# PIC32CX2051BZ66048 device description
Architecture: CORTEX-M4; Family: PIC32CX; Series: PIC32CXBZ66
Registers are 32-bit, read-write, reset 0x0 unless marked. A register's access mark holds for its fields unless they carry their own. Offsets are from the block's base; [hi:lo] are bit positions; {n}, {i} and the like mark numbered series; 'fields as' and 'values as' point back to an identical list.

## DSCON
Instances: DSCON 0x42011000
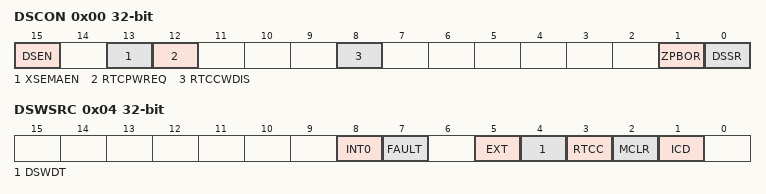
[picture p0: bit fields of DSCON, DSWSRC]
0x00 DSCON
  [15] DSEN, [13] XSEMAEN, [12] RTCPWREQ, [8] RTCCWDIS, [1] ZPBOR, [0] DSSR
0x04 DSWSRC
  [8] INT0, [7] FAULT, [5] EXT, [4] DSWDT, [3] RTCC, [2] MCLR, [1] ICD
0x08 DSSEMA1
  [31:0] DSSEMA
0x10 DSXSEMA1
  [31:0] DSXSEMA

## DSU — Device Service Unit
Instances: DSU 0x41000000
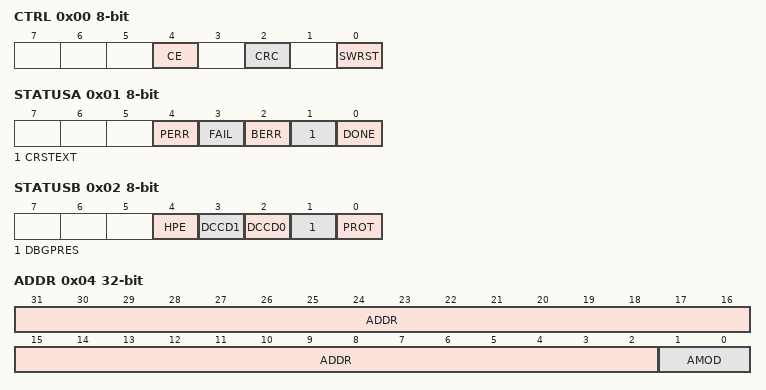
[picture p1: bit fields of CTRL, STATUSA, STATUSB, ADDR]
0x00 CTRL 8-bit wo — Control
  [4] CE — Chip-Erase
  [2] CRC — 32-bit Cyclic Redundancy Code
  [0] SWRST — Software Reset
0x01 STATUSA 8-bit
  [4] PERR — Protection Error
  [3] FAIL — Failure
  [2] BERR — Bus Error
  [1] CRSTEXT — CPU Reset Phase Extension
  [0] DONE
0x02 STATUSB 8-bit ro
  [4] HPE — Hot-Plugging Enable
  [3] DCCD1 — Debug Communication Channel 1 Dirty
  [2] DCCD0 — Debug Communication Channel 0 Dirty
  [1] DBGPRES — Debugger Present
  [0] PROT — Protected
0x04 ADDR — Address
  [31:2] ADDR — Address
  [1:0] AMOD — Access Mode
0x08 LENGTH
  [31:2] LENGTH
0x0C DATA
{0x10+4i} DCC[{i}] (i=0..1) — Debug Communication Channel n
  [31:0] DATA
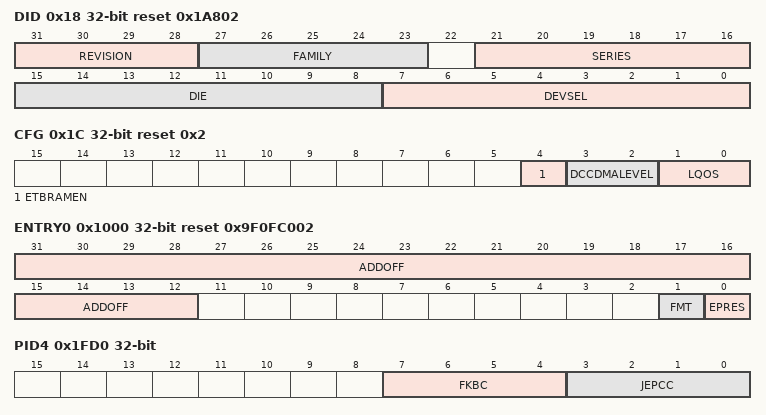
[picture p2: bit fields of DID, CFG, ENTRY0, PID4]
0x18 DID ro reset 0x1A802 — Device Identification
  [31:28] REVISION — Revision Number
  [27:23] FAMILY
  [21:16] SERIES
  [15:8] DIE — Die Number
  [7:0] DEVSEL — Device Select
0x1C CFG reset 0x2 — Configuration
  [4] ETBRAMEN — Trace Control
  [3:2] DCCDMALEVEL — DMA Trigger Level
    0=EMPTY (Trigger rises when DCC is empty); 1=FULL (Trigger rises when DCC is full)
  [1:0] LQOS — Latency Quality Of Service
{0x38+4i} UUID[{i}] (i=0..3) ro — Unique Identifier n
0x48 SECCFG ro — Secure Config
0x4C CTR_STAT ro — RoT Rollback counter
  [7:0] ROLLBACK_CTR — Rollback counter
0x50 BOOT_STAT ro — RoT Boot Status
  [7:0] BOOT_STATUS
{0x54+4i} BOOT_KEY[{i}] (i=0..11) ro — Secure Boot Key n
  [31:0] BOOT_KEY — Secure Boot Key
0x1000 ENTRY0 ro reset 0x9F0FC002 — CoreSight ROM Table Entry 0
  [31:12] ADDOFF — Address Offset
  [1] FMT — Format
  [0] EPRES — Entry Present
0x1004 ENTRY1 ro — CoreSight ROM Table Entry 1
0x1008 END ro — CoreSight ROM Table End
  [31:0] END — End Marker
0x1FCC MEMTYPE ro — CoreSight ROM Table Memory Type
  [0] SMEMP — System Memory Present
0x1FD0 PID4 ro — Peripheral Identification 4
  [7:4] FKBC — 4KB count
  [3:0] JEPCC — JEP-106 Continuation Code
0x1FE0 PID0 ro reset 0xD0 — Peripheral Identification 0
  [7:0] PARTNBL — Part Number Low
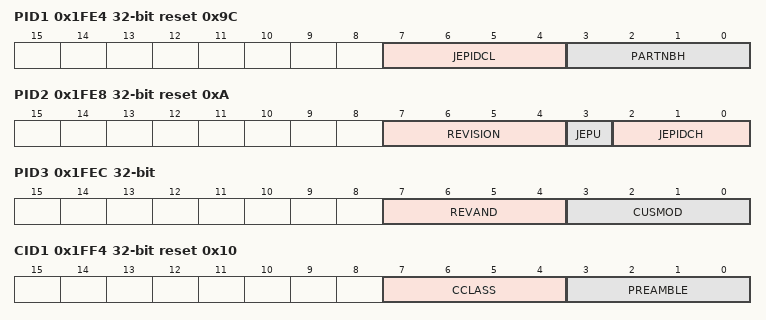
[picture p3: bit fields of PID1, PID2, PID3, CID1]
0x1FE4 PID1 ro reset 0x9C — Peripheral Identification 1
  [7:4] JEPIDCL — Low part of the JEP-106 Identity Code
  [3:0] PARTNBH — Part Number High
0x1FE8 PID2 ro reset 0xA — Peripheral Identification 2
  [7:4] REVISION — Revision Number
  [3] JEPU — JEP-106 Identity Code is used
  [2:0] JEPIDCH — JEP-106 Identity Code High
0x1FEC PID3 ro — Peripheral Identification 3
  [7:4] REVAND — Revision Number
  [3:0] CUSMOD — ARM CUSMOD
0x1FF0 CID0 ro reset 0xD — Component Identification 0
  [7:0] PREAMBLEB0 — Preamble Byte 0
0x1FF4 CID1 ro reset 0x10 — Component Identification 1
  [7:4] CCLASS — Component Class
  [3:0] PREAMBLE
0x1FF8 CID2 ro reset 0x5 — Component Identification 2
  [7:0] PREAMBLEB2 — Preamble Byte 2
0x1FFC CID3 ro reset 0xB1 — Component Identification 3
  [7:0] PREAMBLEB3 — Preamble Byte 3

## EIC — External Interrupt Controller
Instances: EIC 0x40000800
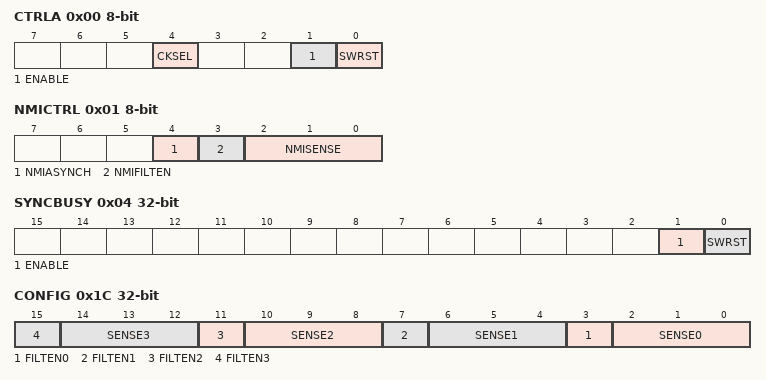
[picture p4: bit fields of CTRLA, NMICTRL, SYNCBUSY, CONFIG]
0x00 CTRLA 8-bit — Control A
  [4] CKSEL — Clock Selection
    0=CLK_GCLK (Clocked by GCLK); 1=32KHZ_LPCLK (Clocked by LPCLK)
  [1] ENABLE
  [0] SWRST — Software Reset
0x01 NMICTRL 8-bit — Non-Maskable Interrupt Control
  [4] NMIASYNCH — Asynchronous Edge Detection Mode
    0=SYNC (Edge detection is clock synchronously operated); 1=ASYNC (Edge detection is clock asynchronously operated)
  [3] NMIFILTEN — Non-Maskable Interrupt Filter Enable
  [2:0] NMISENSE — Non-Maskable Interrupt Sense Configuration
    0=NONE (No detection); 1=RISE (Rising-edge detection); 2=FALL (Falling-edge detection); 3=BOTH (Both-edges detection); 4=HIGH (High-level detection); 5=LOW (Low-level detection)
0x02 NMIFLAG 16-bit (atomic clear) — Non-Maskable Interrupt Flag Status and Clear
  [0] NMI — Non-Maskable Interrupt
0x04 SYNCBUSY ro — Synchronization Busy
  [1] ENABLE — Enable Synchronization Busy Status
  [0] SWRST — Software Reset Synchronization Busy Status
0x08 EVCTRL — Event Control
  [3:0] EXTINTEO — External Interrupt Event Output Enable
0x0C INTENCLR (atomic clear) — Interrupt Enable Clear
  [3:0] EXTINT — External Interrupt Enable
0x10 INTENSET (atomic set) — Interrupt Enable Set
  [3:0] EXTINT — External Interrupt Enable
0x14 INTFLAG (atomic clear) — Interrupt Flag Status and Clear
  [3:0] EXTINT — External Interrupt
0x18 ASYNCH — External Interrupt Asynchronous Mode
  [3:0] ASYNCH — Asynchronous Edge Detection Mode
    values as NMICTRL.NMIASYNCH
0x1C CONFIG — External Interrupt Sense Configuration
  [4n+3] FILTEN{n} (n=0..3) — Filter Enable {n}
  [4n+2:4n] SENSE{n} (n=0..3) — Input Sense Configuration {n}
    0=NONE (No detection); 1=RISE (Rising edge detection); 2=FALL (Falling edge detection); 3=BOTH (Both edges detection); 4=HIGH (High level detection); 5=LOW (Low level detection)
0x30 DEBOUNCEN — Debouncer Enable
  [3:0] DEBOUNCEN
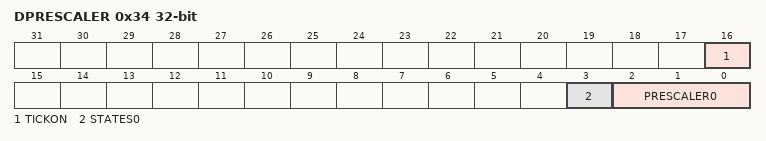
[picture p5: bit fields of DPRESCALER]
0x34 DPRESCALER — Debouncer Prescaler
  [16] TICKON — Pin Sampler frequency selection
    0=CLK_GCLK_EIC (Clocked by GCLK); 1=CLK_LFREQ (Clocked by Low Frequency Clock)
  [3] STATES0 — Debouncer number of states
    0=LFREQ3 (3 low frequency samples); 1=LFREQ7 (7 low frequency samples)
  [2:0] PRESCALER0 — Debouncer Prescaler
    0=DIV2 (EIC clock divided by 2); 1=DIV4 (EIC clock divided by 4); 2=DIV8 (EIC clock divided by 8); 3=DIV16 (EIC clock divided by 16); 4=DIV32 (EIC clock divided by 32); 5=DIV64 (EIC clock divided by 64); 6=DIV128 (EIC clock divided by 128); 7=DIV256 (EIC clock divided by 256)
0x38 PINSTATE ro
  [3:0] PINSTATE
